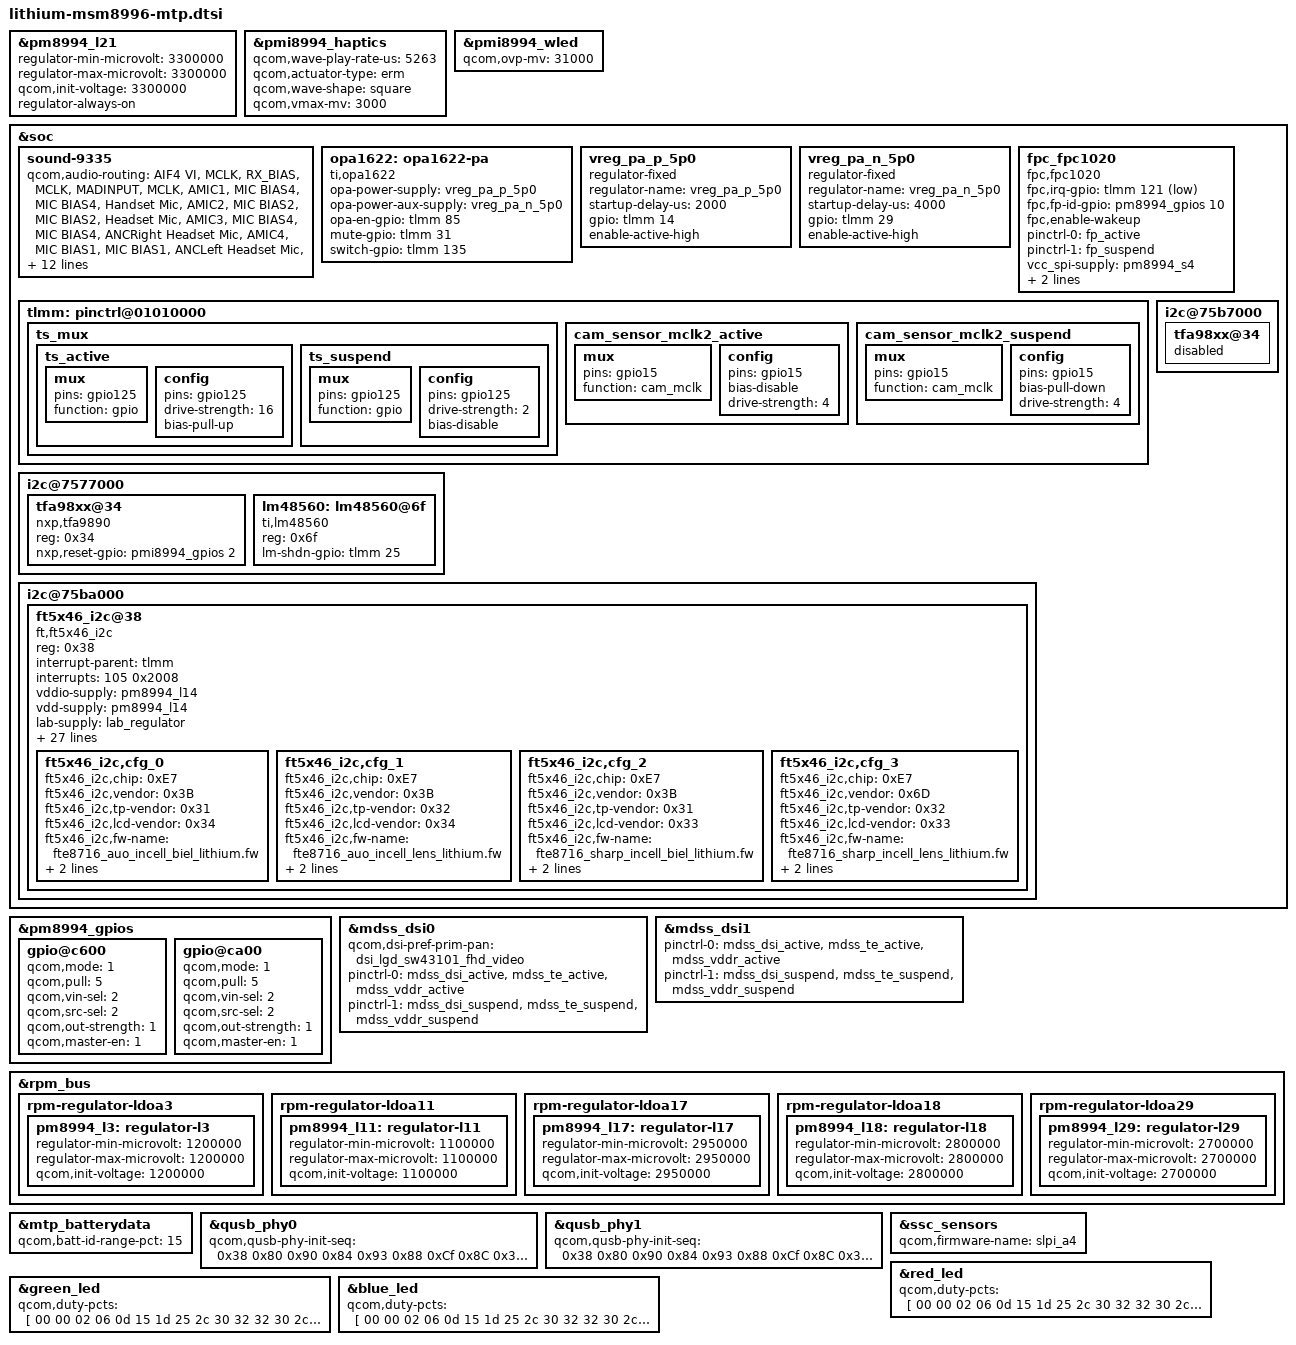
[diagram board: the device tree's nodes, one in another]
/* Copyright (c) 2015, The Linux Foundation. All rights reserved.
 * Copyright (C) 2016 XiaoMi, Inc.
 *
 * This program is free software; you can redistribute it and/or modify
 * it under the terms of the GNU General Public License version 2 and
 * only version 2 as published by the Free Software Foundation.
 *
 * This program is distributed in the hope that it will be useful,
 * but WITHOUT ANY WARRANTY; without even the implied warranty of
 * MERCHANTABILITY or FITNESS FOR A PARTICULAR PURPOSE.  See the
 * GNU General Public License for more details.
 */

#include "msm8996-xiaomi-common.dtsi"
#include "msm8996-camera-sensor-lithium.dtsi"

&pm8994_l21 {
	regulator-min-microvolt = <3300000>;
	regulator-max-microvolt = <3300000>;
	qcom,init-voltage = <3300000>;
	regulator-always-on;
};

&pmi8994_haptics {
	status = "ok";
	qcom,wave-play-rate-us = <5263>;
	qcom,actuator-type = "erm";
	qcom,wave-shape = "square";
	qcom,vmax-mv = <3000>;
};

&pmi8994_wled {
	qcom,ovp-mv = <31000>;
};

&soc {
	sound-9335 {
		qcom,audio-routing =
			"AIF4 VI", "MCLK",
			"RX_BIAS", "MCLK",
			"MADINPUT", "MCLK",
			"AMIC1", "MIC BIAS4",
			"MIC BIAS4", "Handset Mic",
			"AMIC2", "MIC BIAS2",
			"MIC BIAS2", "Headset Mic",
			"AMIC3", "MIC BIAS4",
			"MIC BIAS4", "ANCRight Headset Mic",
			"AMIC4", "MIC BIAS1",
			"MIC BIAS1", "ANCLeft Headset Mic",
			"AMIC5", "MIC BIAS1",
			"MIC BIAS1", "Handset Mic",
			"AMIC6", "MIC BIAS4",
			"MIC BIAS4", "Analog Mic6";

		qcom,audio-routing-p2 =
			"AIF4 VI", "MCLK",
			"RX_BIAS", "MCLK",
			"MADINPUT", "MCLK",
			"AMIC1", "MIC BIAS1",
			"MIC BIAS1", "Handset Mic",
			"AMIC2", "MIC BIAS2",
			"MIC BIAS2", "Headset Mic",
			"AMIC3", "MIC BIAS4",
			"MIC BIAS4", "ANCRight Headset Mic",
			"AMIC4", "MIC BIAS4",
			"MIC BIAS4", "ANCLeft Headset Mic";

		qcom,pa-devs = <&opa1622>;
		qcom,pa-dev-prefix = "OPA";
		qcom,piezo-devs = <&lm48560>;
		qcom,piezo-dev-prefix = "PIEZO";
	};

	opa1622: opa1622-pa {
		compatible = "ti,opa1622";
		opa-power-supply = <&vreg_pa_p_5p0>;
		opa-power-aux-supply = <&vreg_pa_n_5p0>;
		opa-en-gpio = <&tlmm 85 0x00>;
		mute-gpio = <&tlmm 31 0x00>;
		switch-gpio = <&tlmm 135 0x00>;
	};

	vreg_pa_p_5p0: vreg_pa_p_5p0 {
		compatible = "regulator-fixed";
		regulator-name = "vreg_pa_p_5p0";
		startup-delay-us=<2000>;
		gpio = <&tlmm 14 0>;
		enable-active-high;
	};

	vreg_pa_n_5p0: vreg_pa_n_5p0 {
		compatible = "regulator-fixed";
		regulator-name = "vreg_pa_n_5p0";
		startup-delay-us=<4000>;
		gpio = <&tlmm 29 0>;
		enable-active-high;
	};

	fpc_fpc1020 {
		compatible = "fpc,fpc1020";
		fpc,irq-gpio	= <&tlmm 121 0x2001>;
		fpc,fp-id-gpio = <&pm8994_gpios 10 0x00>;
		fpc,enable-wakeup;
		pinctrl-names = "pmx_fp_active", "pmx_fp_suspend";
		pinctrl-0 = <&fp_active>;
		pinctrl-1 = <&fp_suspend>;
		vcc_spi-supply	= <&pm8994_s4>;
		vdd_ana-supply	= <&pm8994_s4>;
		vdd_io-supply	= <&pm8994_s4>;
	};

	tlmm: pinctrl@01010000 {
		ts_mux {
			ts_active: ts_active {
				mux {
					pins = "gpio125";
					function = "gpio";
				};

				config {
					pins = "gpio125";
					drive-strength = <16>;
					bias-pull-up;
				};
			};

			ts_suspend: ts_suspend {
				mux {
					pins = "gpio125";
					function = "gpio";
				};


				config {
					pins = "gpio125";
					drive-strength = <2>;
					bias-disable;
				};
			};
		};

		cam_sensor_mclk2_active: cam_sensor_mclk2_active {
			/* MCLK1 */
			mux {
				/* CLK, DATA */
				pins = "gpio15";
				function = "cam_mclk";
			};
			config {
				pins = "gpio15";
				bias-disable; /* No PULL */
				drive-strength = <4>; /* 4 MA */
			};
		};
		cam_sensor_mclk2_suspend: cam_sensor_mclk2_suspend{
			/* MCLK1 */
			mux {
				/* CLK, DATA */
				pins = "gpio15";
				function = "cam_mclk";
			};
			config {
				pins = "gpio15";
				bias-pull-down; /* PULL DOWN */
				drive-strength = <4>; /* 4 MA */
			};
		};
	};

	i2c@7577000 {
		status = "okay";

		tfa98xx@34 {
			reg = <0x34>;
			compatible = "nxp,tfa9890";
			nxp,reset-gpio = <&pmi8994_gpios 2 0>;
		};

		lm48560: lm48560@6f {
			compatible = "ti,lm48560";
			reg = <0x6f>;
			lm-shdn-gpio = <&tlmm 25 0x00>;
		};
	};

	i2c@75b7000 {
		tfa98xx@34 {
			status = "disabled";
		};
	};

	i2c@75ba000 {
		ft5x46_i2c@38 {
			compatible = "ft,ft5x46_i2c";
			reg = <0x38>;
			interrupt-parent = <&tlmm>;
			interrupts = <105 0x2008>;
			vddio-supply = <&pm8994_l14>;
			vdd-supply = <&pm8994_l14>;
			lab-supply = <&lab_regulator>;
			ibb-supply = <&ibb_regulator>;
			/* pins used by touchscreen */
			pinctrl-names = "pmx_ts_active","pmx_ts_suspend";
			pinctrl-0 = <&ts_active>;
			pinctrl-1 = <&ts_suspend>;
			ft5x46_i2c,i2c-pull-up;
			ft5x46_i2c,irqflags = <0x2008>;
			ft5x46_i2c,x-max = <1080>;
			ft5x46_i2c,y-max = <2040>;
			ft5x46_i2c,z-max = <255>;
			ft5x46_i2c,w-max = <200>;
			ft5x46_i2c,reset-gpio = <&tlmm 89 0x00>;
			ft5x46_i2c,irq-gpio = <&tlmm 125 0x2008>;
			ft5x46_i2c,skip-reset-in-resume;
			ft5x46_i2c,landing-jiffies = <1000>;
			ft5x46_i2c,landing-threshold = <16>;
			ft5x46_i2c,staying-threshold = <8>;
			ft5x46_i2c,raw-min = <7000>;
			ft5x46_i2c,raw-max = <10000>;
			ft5x46_i2c,open-min = <60>;
			ft5x46_i2c,open-max = <200>;
			ft5x46_i2c,short-min = <200>;
			ft5x46_i2c,short-max = <100000000>;
			ft5x46_i2c,fw-delay-55-ms = <2>;
			ft5x46_i2c,fw-delay-aa-ms = <2>;
			ft5x46_i2c,fw-upgrade-id1 = <0xE7>;
			ft5x46_i2c,fw-upgrade-id2 = <0xA6>;
			ft5x46_i2c,fw-delay-readid-ms = <20>;
			ft5x46_i2c,firmware-array-size = <4>;
			ft5x46_i2c,cfg_0 {
				ft5x46_i2c,chip = <0xE7>;
				ft5x46_i2c,vendor = <0x3B>;
				ft5x46_i2c,tp-vendor = <0x31>;
				ft5x46_i2c,lcd-vendor = <0x34>;
				ft5x46_i2c,fw-name = "fte8716_auo_incell_biel_lithium.fw";
				ft5x46_i2c,tx-num = <24>;
				ft5x46_i2c,rx-num = <13>;
			};
			ft5x46_i2c,cfg_1 {
				ft5x46_i2c,chip = <0xE7>;
				ft5x46_i2c,vendor = <0x3B>;
				ft5x46_i2c,tp-vendor = <0x32>;
				ft5x46_i2c,lcd-vendor = <0x34>;
				ft5x46_i2c,fw-name = "fte8716_auo_incell_lens_lithium.fw";
				ft5x46_i2c,tx-num = <24>;
				ft5x46_i2c,rx-num = <13>;
			};
			ft5x46_i2c,cfg_2 {
				ft5x46_i2c,chip = <0xE7>;
				ft5x46_i2c,vendor = <0x3B>;
				ft5x46_i2c,tp-vendor = <0x31>;
				ft5x46_i2c,lcd-vendor = <0x33>;
				ft5x46_i2c,fw-name = "fte8716_sharp_incell_biel_lithium.fw";
				ft5x46_i2c,tx-num = <24>;
				ft5x46_i2c,rx-num = <13>;
			};
			ft5x46_i2c,cfg_3 {
				ft5x46_i2c,chip = <0xE7>;
				ft5x46_i2c,vendor = <0x6D>;
				ft5x46_i2c,tp-vendor = <0x32>;
				ft5x46_i2c,lcd-vendor = <0x33>;
				ft5x46_i2c,fw-name = "fte8716_sharp_incell_lens_lithium.fw";
				ft5x46_i2c,tx-num = <24>;
				ft5x46_i2c,rx-num = <13>;
			};
		};
	};
};

&pm8994_gpios {
	gpio@c600 {
		qcom,mode = <1>;		/* Digital out */
		qcom,pull = <5>;		/* NO PULL */
		qcom,vin-sel = <2>;		/* Logical 1 voltage value 1.8v */
		qcom,src-sel = <2>;		/* QPNP_PIN_SEL_FUNC_CONSTANT */
		qcom,pull = <5>;		/* NO PULL */
		qcom,out-strength = <1>;	/* Low drive strength */
		qcom,master-en = <1>;
		status = "okay";
	};

	gpio@ca00 {
		qcom,mode = <1>;		/* Digital out */ qcom,pull = <5>;		/* NO PULL */
		qcom,vin-sel = <2>;		/* Logical 1 voltage value 1.8v */
		qcom,src-sel = <2>;		/* QPNP_PIN_SEL_FUNC_CONSTANT */
		qcom,pull = <5>;		/* NO PULL */
		qcom,out-strength = <1>;	/* Low drive strength */
		qcom,master-en = <1>;
		status = "okay";
	};
};

&mdss_dsi0 {
	qcom,dsi-pref-prim-pan = <&dsi_lgd_sw43101_fhd_video>;
	pinctrl-names = "mdss_default", "mdss_sleep";
	pinctrl-0 = <&mdss_dsi_active &mdss_te_active &mdss_vddr_active>;
	pinctrl-1 = <&mdss_dsi_suspend &mdss_te_suspend &mdss_vddr_suspend>;
};

&mdss_dsi1 {
	pinctrl-names = "mdss_default", "mdss_sleep";
	pinctrl-0 = <&mdss_dsi_active &mdss_te_active &mdss_vddr_active>;
	pinctrl-1 = <&mdss_dsi_suspend &mdss_te_suspend &mdss_vddr_suspend>;
};

&rpm_bus {
	rpm-regulator-ldoa3 {
		status = "okay";
		pm8994_l3: regulator-l3 {
			regulator-min-microvolt = <1200000>;
			regulator-max-microvolt = <1200000>;
			qcom,init-voltage = <1200000>;
			status = "okay";
		};
	};

	rpm-regulator-ldoa11 {
		status = "okay";
		pm8994_l11: regulator-l11 {
			regulator-min-microvolt = <1100000>;
			regulator-max-microvolt = <1100000>;
			qcom,init-voltage = <1100000>;
			status = "okay";
		};
	};

	rpm-regulator-ldoa17 {
		status = "okay";
		pm8994_l17: regulator-l17 {
			regulator-min-microvolt = <2950000>;
			regulator-max-microvolt = <2950000>;
			qcom,init-voltage = <2950000>;
			status = "okay";
		};
	};

	rpm-regulator-ldoa18 {
		status = "okay";
		pm8994_l18: regulator-l18 {
			regulator-min-microvolt = <2800000>;
			regulator-max-microvolt = <2800000>;
			qcom,init-voltage = <2800000>;
			status = "okay";
		};
	};

	rpm-regulator-ldoa29 {
		status = "okay";
		pm8994_l29: regulator-l29 {
			regulator-min-microvolt = <2700000>;
			regulator-max-microvolt = <2700000>;
			qcom,init-voltage = <2700000>;
			status = "okay";
		};
	};
};

&mtp_batterydata {
	qcom,batt-id-range-pct = <15>;
	#include "batterydata-lithium-atl-4400mah.dtsi"
};

&qusb_phy0 {
	qcom,qusb-phy-init-seq = <0x38 0x80
			0x90 0x84
			0x93 0x88
			0xCf 0x8C
			0x30 0x08
			0x79 0x0C
			0x21 0x10
			0x14 0x9C
			0x9F 0x1C
			0x00 0x18>;
};

&qusb_phy1 {
	qcom,qusb-phy-init-seq = <0x38 0x80
			0x90 0x84
			0x93 0x88
			0xCf 0x8C
			0x30 0x08
			0x79 0x0C
			0x21 0x10
			0x14 0x9C
			0x9F 0x1C
			0x00 0x18>;
};

&ssc_sensors {
	qcom,firmware-name = "slpi_a4";
};

&red_led {
	qcom,duty-pcts = [
		00 00 02 06 0d 15
		1d 25 2c 30 32
		32 30 2c 25 1d
		15 0d 06 02 00
		00];
};

&green_led {
	qcom,duty-pcts = [
		00 00 02 06 0d 15
		1d 25 2c 30 32
		32 30 2c 25 1d
		15 0d 06 02 00
		00];
};

&blue_led {
	qcom,duty-pcts = [
		00 00 02 06 0d 15
		1d 25 2c 30 32
		32 30 2c 25 1d
		15 0d 06 02 00
		00];
};
